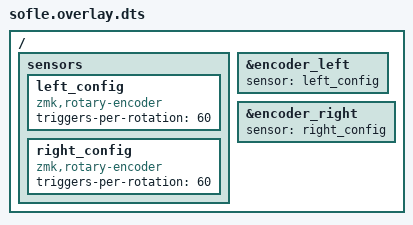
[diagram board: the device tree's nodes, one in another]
/ {
    sensors {
        left_config: left_config {
            compatible = "zmk,rotary-encoder";
            triggers-per-rotation = <60>;
        };

        right_config: right_config {
            compatible = "zmk,rotary-encoder";
            triggers-per-rotation = <60>;
        };
    };
};

/ {
    &encoder_left {
        sensor = <&left_config>;
    };

    &encoder_right {
        sensor = <&right_config>;
    };
};
